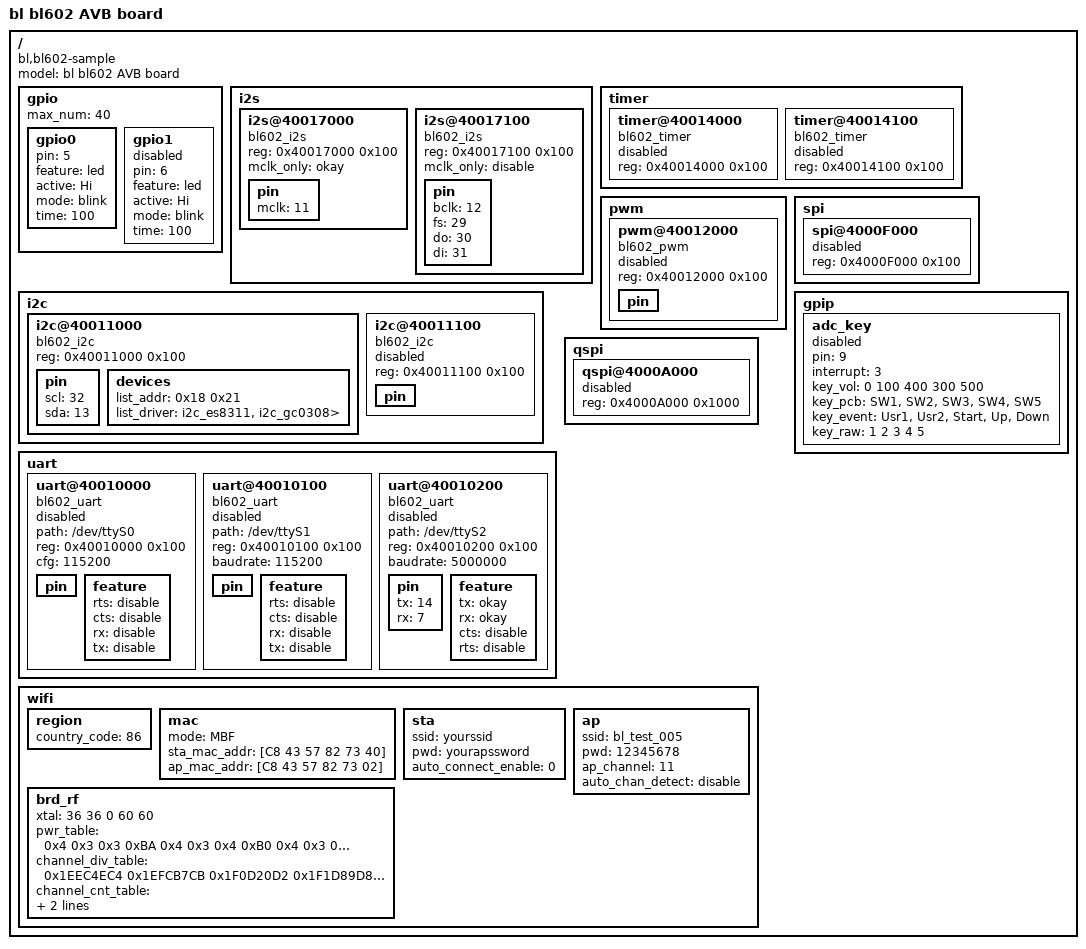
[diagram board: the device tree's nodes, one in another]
/dts-v1/;
// version: 17
// last_comp_version: 16
// boot_cpuid_phys: 0x0

/ {
    model = "bl bl602 AVB board";
    compatible = "bl,bl602-sample", "bl,bl602-common";
    #address-cells = <0x1>;
    #size-cells = <0x1>;
    gpio {
        #address-cells = <1>;
        #size-cells = <1>;
        max_num = <40>;
        gpio0 {                                  
            status = "okay";                     
            pin  = <5>;                          
            feature = "led";                     
            active = "Hi"; //Hi or Lo
            mode = "blink"; //blink or hearbeat
            time = <100>; //duration for this mode
        };
        gpio1 {                                  
            status = "disable";                     
            pin  = <6>;                          
            feature = "led";                     
            active = "Hi"; //Hi or Lo
            mode = "blink"; //blink or hearbeat
            time = <100>; //duration for this mode
        };
    };
    i2s {
        #address-cells = <1>;
        #size-cells = <1>;
        i2s@40017000 {
            status = "okay";
            compatible = "bl602_i2s";
            reg = <0x40017000 0x100>;
            mclk_only = "okay";
            pin {
                mclk = <11>;
            };
        };
        i2s@40017100 {
            status = "okay";
            compatible = "bl602_i2s";
            reg = <0x40017100 0x100>;
            mclk_only = "disable";
            pin {
                bclk = <12>;
                fs = <29>;
                do = <30>;
                di = <31>;
            };
        };
    };
    i2c {
        #address-cells = <1>;
        #size-cells = <1>;
        i2c@40011000 {
            status = "okay";
            compatible = "bl602_i2c";
            reg = <0x40011000 0x100>;
            pin {
                scl = <32>;
                sda = <13>;
            };
            devices {
                list_addr = <0x18 0x21>;
                list_driver = "i2c_es8311", "i2c_gc0308>";
            };
        };
        i2c@40011100 {
            status = "disable";
            compatible = "bl602_i2c";
            reg = <0x40011100 0x100>;
            pin {
                /*empty here*/
            };
        };
    };
    timer {
        #address-cells = <1>;
        #size-cells = <1>;
        timer@40014000 {
            status = "disable";
            compatible = "bl602_timer";
            reg = <0x40014000 0x100>;
        };
        timer@40014100 {
            status = "disable";
            compatible = "bl602_timer";
            reg = <0x40014100 0x100>;
        };
    };
    pwm {
        #address-cells = <1>;
        #size-cells = <1>;
        pwm@40012000 {
            status = "disable";
            compatible = "bl602_pwm";
            reg = <0x40012000 0x100>;
            pin {
                /*empty here*/
            };
        };
    };
    uart {
        #address-cells = <1>;
        #size-cells = <1>;
        uart@40010000 {
            status = "disable";
            compatible = "bl602_uart";
            path = "/dev/ttyS0";
            reg = <0x40010000 0x100>;
            cfg = <115200>;
            pin {
                /*empty here*/
            };
            feature {
                rts = "disable";
                cts = "disable";
                rx = "disable";
                tx = "disable";
            };
        };
        uart@40010100 {
            status = "disable";
            compatible = "bl602_uart";
            path = "/dev/ttyS1";
            reg = <0x40010100 0x100>;
            baudrate = <115200>;
            pin {
                /*empty here*/
            };
            feature {
                rts = "disable";
                cts = "disable";
                rx = "disable";
                tx = "disable";
            };
        };
        uart@40010200 {
            status = "enable";
            compatible = "bl602_uart";
            path = "/dev/ttyS2";
            reg = <0x40010200 0x100>;
            baudrate = <5000000>;
            pin {
                tx = <14>;
                rx = <7>;
            };
            feature {
                tx = "okay";
                rx = "okay";
                cts = "disable";
                rts = "disable";
            };
        };
    };
    spi {
        #address-cells = <1>;
        #size-cells = <1>;
        spi@4000F000 {
            status = "disable";
            reg = <0x4000F000 0x100>;/* 4KB */
        };
    };
    gpip {
        #address-cells = <1>;
        #size-cells = <1>;
        adc_key {
            status = "disable";
            pin = <9>;
            interrupt  = <3>;
            key_vol = <0 100 400 300 500>;
            key_pcb = "SW1", "SW2", "SW3", "SW4","SW5";
            key_event = "Usr1", "Usr2", "Start", "Up", "Down";
            key_raw = <1 2 3 4 5>;
        };
    };
    qspi {
        #address-cells = <1>;
        #size-cells = <1>;
        qspi@4000A000 {
            status = "disable";
            reg = <0x4000A000 0x1000>;/* 4KB */
        };
    };
    wifi {
        #address-cells = <1>;
        #size-cells = <1>;
        region {
            country_code = <86>;
        };
        mac {
            mode = "MBF";
            sta_mac_addr = [C8 43 57 82 73 40];
            ap_mac_addr = [C8 43 57 82 73 02];
        };
        sta {
            ssid = "yourssid";
            pwd = "yourapssword";
            auto_connect_enable = <0>;
        };
        ap {
            ssid = "bl_test_005";
            pwd = "12345678";
            ap_channel = <11>;
            auto_chan_detect = "disable";
        };
        brd_rf {
            xtal = <36 36 0 60 60>;
            /*
            pwr_table = <   4 3 3 186
                            4 3 4 176
                            4 3 5 167
                            3 3 0 159
                            3 3 1 149
                            3 3 2 140
                            3 3 3 129
                            3 3 4 119
                            3 3 5 110
                            2 3 0 101
                            2 3 1 91
                            2 3 2 82
                            2 3 3 72
                            2 3 4 62
                            2 3 5 52
                            1 3 3 10>;
            */
            pwr_table = <0x4 0x3 0x3 0xBA 0x4 0x3 0x4 0xB0 0x4 0x3 0x5 0xA7 0x3 0x3 0x0 0x9F 0x3 0x3 0x1 0x95 0x3 0x3 0x2 0x8C 0x3 0x3 0x3 0x81 0x3 0x3 0x4 0x77 0x3 0x3 0x5 0x6E 0x2 0x3 0x0 0x65 0x2 0x3 0x1 0x5B 0x2 0x3 0x2 0x52 0x2 0x3 0x3 0x48 0x2 0x3 0x4 0x3E 0x2 0x3 0x5 0x34 0x1 0x3 0x3 0xA>;
            channel_div_table = <0x1EEC4EC4 0x1EFCB7CB 0x1F0D20D2 0x1F1D89D8 0x1F2DF2DF 0x1F3E5BE5 0x1F4EC4EC 0x1F5F2DF2 0x1F6F96F9 0x1F800000 0x1F906906 0x1FA0D20D 0x1FB13B13 0x1FD89D89 0x201F81F8>;
            channel_cnt_table = <0xA78A 0xA7E3 0xA83C 0xA895 0xA8ED 0xA946 0xA99F 0xA9F8 0xAA51 0xAAAA 0xAB03 0xAB5C 0xABB5 0xAC8A>;
            lo_fcal_div = <0x56B>;
        };
    };
};
